# DA1469x register map
Vendor: Dialog; Series: DA1469x; File version: 1.2
CPU: CM33 r1p0, little endian, no MPU, FPU, 3 interrupt priority bits
Registers are 32-bit, read-write, reset 0x0 unless marked. A register's access mark holds for its fields unless they carry their own. Offsets are from the block's base; [hi:lo] are bit positions; {n}, {i} and the like mark numbered series; 'fields as' and 'values as' point back to an identical list.

## GPIO — GPIO registers
Base 0x50020A00
0x00 P0_DATA_REG reset 0x1410 (reset mask 0x7FFFFFFF) — P0 Data input / output Register
  [31:0] P0_DATA — Set P0 output register when written; Returns the value of P0 port when read
0x04 P1_DATA_REG — P1 Data input / output Register
  [22:0] P1_DATA — Set P1 output register when written; Returns the value of P1 port when read
0x08 P0_SET_DATA_REG (reset mask 0x7FFFFFFF) — P0 Set port pins Register
  [31:0] P0_SET wo — Writing a 1 to P0[y] sets P0[y] to 1. Writing 0 is discarded; Reading returns 0
0x0C P1_SET_DATA_REG — P1 Set port pins Register
  [22:0] P1_SET wo — Writing a 1 to P1[y] sets P1[y] to 1. Writing 0 is discarded; Reading returns 0
0x10 P0_RESET_DATA_REG (reset mask 0x7FFFFFFF) — P0 Reset port pins Register
  [31:0] P0_RESET wo — Writing a 1 to P0[y] sets P0[y] to 0. Writing 0 is discarded; Reading returns 0
0x14 P1_RESET_DATA_REG — P1 Reset port pins Register
  [22:0] P1_RESET wo — Writing a 1 to P1[y] sets P1[y] to 0. Writing 0 is discarded; Reading returns 0
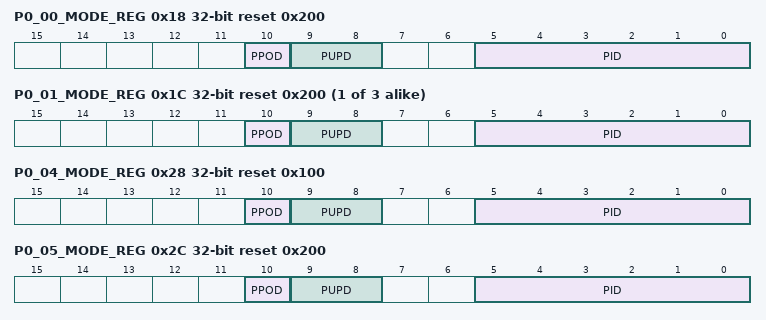
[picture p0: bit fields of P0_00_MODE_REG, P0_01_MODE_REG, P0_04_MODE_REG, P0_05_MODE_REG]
0x18 P0_00_MODE_REG reset 0x200 — P0_00 Mode Register
  [10] PPOD — 0: Push pull 1: Open drain
  [9:8] PUPD — 00 = Input, no resistors selected 01 = Input, pull-up selected 10 = Input, pull-down selected 11 = Output, no resistors selected In ADC mode, these bits are don't care
  [5:0] PID — Function of port: 0: GPIO (see also the PUPD bit-field) 1: UART_RX 2: UART_TX 3: UART2_RX 4: UART2_TX 5: UART2_CTSN 6: UART2_RTSN 7: UART3_RX 8: UART3_TX 9: UART3_CTSN 10: UART3_RTSN 11: ISO_CLK 12: ISO_DATA 13: SPI_DI 14: SPI_DO 15: SPI_CLK16: SPI_EN 17: SPI2_DI 18: SPI2_DO 19: SPI2_CLK 20: SPI2_EN 21: I2C_SCL 22: I2C_SDA 23: I2C2_SCL 24: I2C2_SDA 25: USB_SOF 26: ADC (dedicated pins, see also the "Input/Output Ports" chapter of Datasheet) 27: USB (dedicated pins P0_14 and P0_15) 28: PCM_DI 29: PCM_DO 30: PCM_FSC 31: PCM_CLK 32: PDM_DATA 33: PDM_CLK 34: COEX_EXT_ACT 35: COEX_SMART_ACT 36: COEX_SMART_PRI 37: PORT0_DCF 38: PORT1_DCF 39: PORT2_DCF 40: PORT3_DCF 41: PORT4_DCF 42: CLOCK (see also GPIO_CLK_SEL_REG for the dedicated pins mapping of supported clocks) 43: PG (dedicated pins, see also the "Input/Output Ports" chapter of Datasheet) 44: LCD (dedicated pins see also the "Input/Output Ports" chapter of Datasheet) 45: LCD_SPI_DC 46: LCD_SPI_DO 47: LCD_SPI_CLK 48: LCD_SPI_EN 49: TIM_PWM 50: TIM2_PWM 51: TIM_1SHOT 52: TIM2_1SHOT 53: TIM3_PWM 54: TIM4_PWM 55: Reserved 56: CMAC_DIAG0 57: CMAC_DIAG1 58: CMAC_DIAG2 59: CMAC_DIAGX (dedicated pins, see also the "Input/Output Ports" chapter of Datasheet) 60: Reserved 61: Reserved 62: Reserved 63: Reserved
{0x18+4i} P0_{i:02}_MODE_REG reset 0x200 (i=1..3) — P0_{i:02} Mode Register
  [10] PPOD — 0: Push pull 1: Open drain
  [9:8] PUPD — 00 = Input, no resistors selected 01 = Input, pull-up selected 10 = Input, pull-down selected 11 = Output, no resistors selected In ADC mode, these bits are don't care
  [5:0] PID — See P0_00_MODE_REG[PID]
0x28 P0_04_MODE_REG reset 0x100 — P0_04 Mode Register
  fields as P0_01_MODE_REG
0x2C P0_05_MODE_REG reset 0x200 — P0_05 Mode Register
  fields as P0_01_MODE_REG
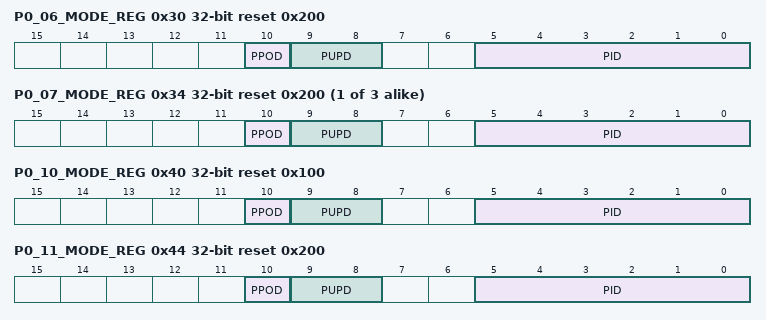
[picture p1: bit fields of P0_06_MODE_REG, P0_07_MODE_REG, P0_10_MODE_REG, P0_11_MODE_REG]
0x30 P0_06_MODE_REG reset 0x200 — P0_06 Mode Register
  fields as P0_01_MODE_REG
{0x18+4i} P0_{i:02}_MODE_REG reset 0x200 (i=7..9) — P0_{i:02} Mode Register
  [10] PPOD — 0: Push pull 1: Open drain
  [9:8] PUPD — 00 = Input, no resistors selected 01 = Input, pull-up selected 10 = Input, pull-down selected 11 = Output, no resistors selected In ADC mode, these bits are don't care.
  [5:0] PID — See P0_00_MODE_REG[PID]
0x40 P0_10_MODE_REG reset 0x100 — P0_10 Mode Register
  fields as P0_07_MODE_REG
0x44 P0_11_MODE_REG reset 0x200 — P0_11 Mode Register
  fields as P0_07_MODE_REG
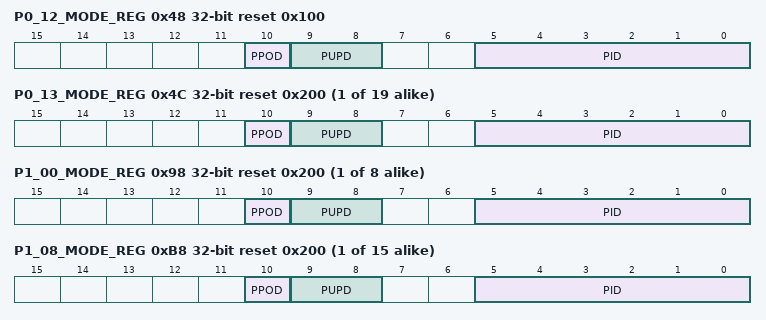
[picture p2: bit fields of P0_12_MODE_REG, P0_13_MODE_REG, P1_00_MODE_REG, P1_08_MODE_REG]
0x48 P0_12_MODE_REG reset 0x100 — P0_12 Mode Register
  fields as P0_07_MODE_REG
{0x18+4i} P0_{i}_MODE_REG reset 0x200 (i=13..31) — P0_{i} Mode Register
  fields as P0_07_MODE_REG
{0x98+4i} P1_{i:02}_MODE_REG reset 0x200 (i=0..7) — P1_{i:02} Mode Register
  fields as P0_01_MODE_REG
{0x98+4i} P1_{i:02}_MODE_REG reset 0x200 (i=8..22) — P1_{i:02} Mode Register
  fields as P0_07_MODE_REG
0xF4 P0_PADPWR_CTRL_REG (reset mask 0x7FFFFFFF) — P0 Output Power Control Register
  [31:6] P0_OUT_CTRL — 0 = P0_x port output is powered by the V30 rail (default) 1 = P0_x port output is powered by the 1V8P rail bit x controls the power supply of P0[x]
0xF8 P1_PADPWR_CTRL_REG — P1 Output Power Control Register
  [22:0] P1_OUT_CTRL — 0 = P1_x port output is powered by the V30 rail (default) 1 = P1_x port output is powered by the 1V8P rail bit x controls the power supply of P1[x]
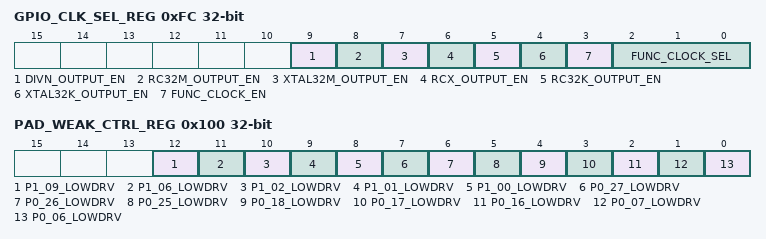
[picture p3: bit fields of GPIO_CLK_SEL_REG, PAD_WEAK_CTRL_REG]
0xFC GPIO_CLK_SEL_REG — Select which clock to map on ports P0/P1
  [9] DIVN_OUTPUT_EN — DIVN output enable bit-field. When set, it enables the mapping of DIVN clock on dedicated GPIO (P0_15). The specific GPIO must be configured as GPIO output.
  [8] RC32M_OUTPUT_EN — RC32M output enable bit-field. When set, it enables the mapping of RC32M clock on dedicated GPIO (P0_13). The specific GPIO must be configured as GPIO output.
  [7] XTAL32M_OUTPUT_EN — XTAL32M output enable bit-field. When set, it enables the mapping of XTAL32M clock on dedicated GPIO (P0_12). The specific GPIO must be configured as GPIO output.
  [6] RCX_OUTPUT_EN — RCX output enable bit-field. When set, it enables the mapping of RCX clock on dedicated GPIO (P0_16). The specific GPIO must be configured as GPIO output.
  [5] RC32K_OUTPUT_EN — RC32K output enable bit-field. When set, it enables the mapping of RC32K clock on dedicated GPIO (P0_17). The specific GPIO must be configured as GPIO output.
  [4] XTAL32K_OUTPUT_EN — XTAL32K output enable bit-field. When set, it enables the mapping of XTAL32K clock on dedicated GPIO (P0_14).The specific GPIO must be configured as GPIO output.
  [3] FUNC_CLOCK_EN — If set, it enables the mapping of the selected clock signal, according to FUNC_CLOCK_SEL bit-field.
  [2:0] FUNC_CLOCK_SEL — Select which clock to map when PID = FUNC_CLOCK. 0x0: XTAL32K 0x1: RC32K 0x2: RCX 0x3: XTAL32M 0x4: RC32M 0x5: DIVN 0x6: Reserved 0x7: Reserved
0x100 PAD_WEAK_CTRL_REG — Weak Pads Control Register
  [12] P1_09_LOWDRV — 0 = Normal operation 1 = Reduces the driving strength of P1_09 pad Note: This mode should be coupled with the selection of VDD1V8P supply rail for the specific pad (see also the description of P1_PADPWDR_CTRL_REG).
  [11] P1_06_LOWDRV — 0 = Normal operation 1 = Reduces the driving strength of P1_06 pad Note: This mode should be coupled with the selection of VDD1V8P supply rail for the specific pad (see also the description of P1_PADPWDR_CTRL_REG).
  [10] P1_02_LOWDRV — 0 = Normal operation 1 = Reduces the driving strength of P1_02 pad Note: This mode should be coupled with the selection of VDD1V8P supply rail for the specific pad (see also the description of P1_PADPWDR_CTRL_REG).
  [9] P1_01_LOWDRV — 0 = Normal operation 1 = Reduces the driving strength of P1_01 pad Note: This mode should be coupled with the selection of VDD1V8P supply rail for the specific pad (see also the description of P1_PADPWDR_CTRL_REG).
  [8] P1_00_LOWDRV — 0 = Normal operation 1 = Reduces the driving strength of P1_00 pad Note: This mode should be coupled with the selection of VDD1V8P supply rail for the specific pad (see also the description of P1_PADPWDR_CTRL_REG).
  [7] P0_27_LOWDRV — 0 = Normal operation 1 = Reduces the driving strength of P0_27 pad Note: This mode should be coupled with the selection of VDD1V8P supply rail for the specific pad (see also the description of P0_PADPWDR_CTRL_REG).
  [6] P0_26_LOWDRV — 0 = Normal operation 1 = Reduces the driving strength of P0_26 pad Note: This mode should be coupled with the selection of VDD1V8P supply rail for the specific pad (see also the description of P0_PADPWDR_CTRL_REG).
  [5] P0_25_LOWDRV — 0 = Normal operation 1 = Reduces the driving strength of P0_25 pad Note: This mode should be coupled with the selection of VDD1V8P supply rail for the specific pad (see also the description of P0_PADPWDR_CTRL_REG).
  [4] P0_18_LOWDRV — 0 = Normal operation 1 = Reduces the driving strength of P0_18 pad Note: This mode should be coupled with the selection of VDD1V8P supply rail for the specific pad (see also the description of P0_PADPWDR_CTRL_REG).
  [3] P0_17_LOWDRV — 0 = Normal operation 1 = Reduces the driving strength of P0_17 pad Note: This mode should be coupled with the selection of VDD1V8P supply rail for the specific pad (see also the description of P0_PADPWDR_CTRL_REG).
  [2] P0_16_LOWDRV — 0 = Normal operation 1 = Reduces the driving strength of P0_16 pad Note: This mode should be coupled with the selection of VDD1V8P supply rail for the specific pad (see also the description of P0_PADPWDR_CTRL_REG).
  [1] P0_07_LOWDRV — 0 = Normal operation 1 = Reduces the driving strength of P0_07 pad Note: This mode should be coupled with the selection of VDD1V8P supply rail for the specific pad (see also the description of P0_PADPWDR_CTRL_REG).
  [0] P0_06_LOWDRV — 0 = Normal operation 1 = Reduces the driving strength of P0_06 pad Note: This mode should be coupled with the selection of VDD1V8P supply rail for the specific pad (see also the description of P0_PADPWDR_CTRL_REG).
